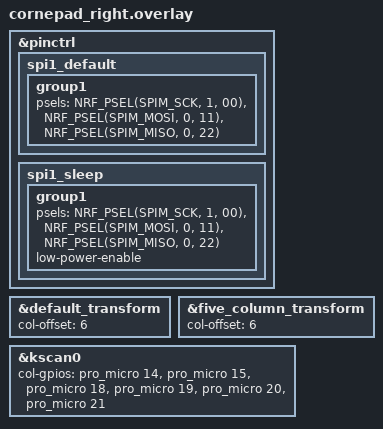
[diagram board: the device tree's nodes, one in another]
/*
 * Copyright (c) 2020 Pete Johanson
 *
 * SPDX-License-Identifier: MIT
 */

#include "cornepad.dtsi"


&pinctrl {
    /* configuration for spi1 device, default state */
    spi1_default: spi1_default {
        /* node name is arbitrary */
        group1 {
            psels = <NRF_PSEL(SPIM_SCK,  1, 00)>,
                    <NRF_PSEL(SPIM_MOSI, 0, 11)>,
                    <NRF_PSEL(SPIM_MISO, 0, 22)>;
        };
    };

    /* configuration for spi1 device, sleep state */
    spi1_sleep: spi1_sleep {
        group1 {
            psels = <NRF_PSEL(SPIM_SCK, 1, 00)>,
                    <NRF_PSEL(SPIM_MOSI, 0, 11)>,
                    <NRF_PSEL(SPIM_MISO, 0, 22)>;
            low-power-enable;
        };
    };

};





&default_transform {
    col-offset = <6>;
};

&five_column_transform {
    col-offset = <6>;
};

&kscan0 {
    col-gpios
        = <&pro_micro 14 GPIO_ACTIVE_HIGH>
        , <&pro_micro 15 GPIO_ACTIVE_HIGH>
        , <&pro_micro 18 GPIO_ACTIVE_HIGH>
        , <&pro_micro 19 GPIO_ACTIVE_HIGH>
        , <&pro_micro 20 GPIO_ACTIVE_HIGH>
        , <&pro_micro 21 GPIO_ACTIVE_HIGH>
        ;
};
